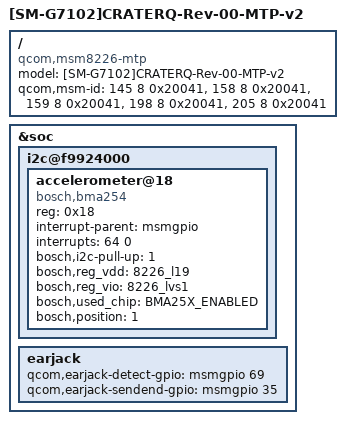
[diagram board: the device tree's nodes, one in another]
/* Copyright (c) 2013, The Linux Foundation. All rights reserved.
 *
 * This program is free software; you can redistribute it and/or modify
 * it under the terms of the GNU General Public License version 2 and
 * only version 2 as published by the Free Software Foundation.
 *
 * This program is distributed in the hope that it will be useful,
 * but WITHOUT ANY WARRANTY; without even the implied warranty of
 * MERCHANTABILITY or FITNESS FOR A PARTICULAR PURPOSE.  See the
 * GNU General Public License for more details.
 */

/* qcom,msm-id =<Chip_id Board_version Other_Specific_info>
 * All these three fields are unsigned 32 bit integers
 * For OtherSpecificInfo = 0xABCDEFGH [32 bits in total]
 *  G[4BITS]:MODEL_VARIANT i.e. 0 for MS01,1 for MILLET_3G
 *  H[4BITS]:Hardware Revision
 * Please refer to .../lk/platform/msm_shared/dev_tree.c also
 */ 

/dts-v1/;
/include/ "msm8226-v2.dtsi"
/include/ "msm8226-sec-craterq3g-r00.dtsi"

/ {
	model = "[SM-G7102]CRATERQ-Rev-00-MTP-v2";
	compatible = "qcom,msm8226-mtp", "qcom,msm8226", "qcom,mtp";
	qcom,msm-id = <145 8 0x20041>,
		      <158 8 0x20041>,
		      <159 8 0x20041>,
		      <198 8 0x20041>,
		      <205 8 0x20041>;
};

&soc {
    i2c@f9924000 { /* BLSP1 QUP2 */
                accelerometer@18 {
                        compatible = "bosch,bma254";
                        reg = <0x18>;
                        interrupt-parent = <&msmgpio>;
                        interrupts = <64 0>;
                        bosch,i2c-pull-up = <1>;
                        bosch,reg_vdd = "8226_l19";
                        bosch,reg_vio = "8226_lvs1";
                        bosch,used_chip = "BMA25X_ENABLED";
                        bosch,position = <1>;
                };
        };

        earjack {

                /*Override GPIO properties*/
                qcom,earjack-detect-gpio = <&msmgpio 69 0>;
                qcom,earjack-sendend-gpio = <&msmgpio 35 0>;

        };
};
